# M55M1 register map
File version: 1.0
Registers are 32-bit, read-write, reset 0x0 unless marked. A register's access mark holds for its fields unless they carry their own. Offsets are from the block's base; [hi:lo] are bit positions.

## LPSPI_NS — LPSPI Register Map
Base 0x50444000
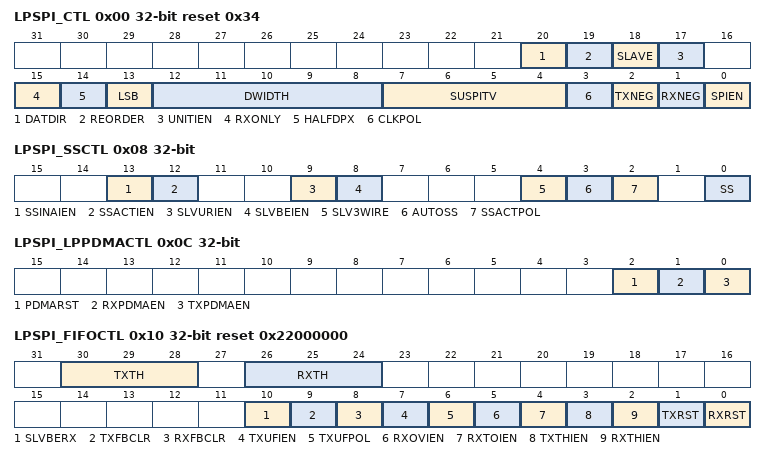
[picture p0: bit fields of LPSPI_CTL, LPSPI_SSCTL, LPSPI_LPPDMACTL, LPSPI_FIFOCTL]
0x00 LPSPI_CTL reset 0x34 — LPSPI Control Register
  [20] DATDIR — Data Port Direction Control. This bit is used to select the data input/output direction in half-duplex transfer and Dual transfer
    0=LPSPI data is input direction; 1=LPSPI data is output direction
  [19] REORDER — Byte Reorder Function Enable Bit. Note: Byte Reorder function is only available if DWIDTH is defined as 16, 24, and 32 bits.
    0=Byte Reorder function Disabled; 1=Byte Reorder function Enabled. A byte suspend interval will be inserted among each byte. The period of the byte suspend interval depends on the setting of SUSPITV
  [18] SLAVE — Slave Mode Control
    0=Master mode; 1=Slave mode
  [17] UNITIEN — Unit Transfer Interrupt Enable Bit
    0=LPSPI unit transfer interrupt Disabled; 1=LPSPI unit transfer interrupt Enabled
  [15] RXONLY — Receive-only Mode Enable Bit. This bit field is only available in Master mode. In receive-only mode, LPSPI Master will generate LPSPI bus clock continuously for receiving data bit from LPSPI slave device and assert the BUSY status. Note: This bit is for Master Mode only.
    0=Receive-only mode Disabled; 1=Receive-only mode Enabled
  [14] HALFDPX — LPSPI Half-duplex Transfer Enable Bit. This bit is used to select full-duplex or half-duplex for LPSPI transfer. The bit field DATDIR (LPSPI_CTL[20]) can be used to set the data direction in half-duplex transfer.
    0=LPSPI operates in full-duplex transfer; 1=LPSPI operates in half-duplex transfer
  [13] LSB — Send LSB First
    0=The MSB, which bit of transmit/receive register depends on the setting of DWIDTH, is transmitted/received first; 1=The LSB, bit 0 of the LPSPI TX register, is sent first to the LPSPI data output pin, and the first bit received from the LPSPI data input pin will be put in the LSB position of the RX register (bit 0 of LPSPI_RX)
  [12:8] DWIDTH — Data Width. This field specifies how many bits can be transmitted/received in one transaction. The minimum bit length is 4 bits and can up to 32 bits. Note: This bit field will decide the depth of TX/RX FIFO configuration in LPSPI mode. Therefore, changing this bit field will clear TX/RX FIFO by hardware automatically.
  [7:4] SUSPITV — Suspend Interval. The four bits provide configurable suspend interval between two successive transmit/receive transaction in a transfer. The definition of the suspend interval is the interval between the last clock edge of the preceding transaction word and the first clock edge of the following transaction word. The default value is 0x3. The period of the suspend interval is obtained according to the following equation. (SUSPITV[3:0] + 0.5) * period of LPSPI_CLK clock cycle. Example: Note: These bits are for Master Mode only.
  [3] CLKPOL — Clock Polarity
    0=LPSPI bus clock is idle low; 1=LPSPI bus clock is idle high
  [2] TXNEG — Transmit on Negative Edge
    0=Transmitted data output signal is changed on the rising edge of LPSPI bus clock; 1=Transmitted data output signal is changed on the falling edge of LPSPI bus clock
  [1] RXNEG — Receive on Negative Edge
    0=Received data input signal is latched on the rising edge of LPSPI bus clock; 1=Received data input signal is latched on the falling edge of LPSPI bus clock
  [0] SPIEN — LPSPI Transfer Control Enable Bit. In Master mode, the transfer will start when there is data in the FIFO buffer after this bit is set to 1. In Slave mode, this device is ready to receive data when this bit is set to 1. Note: Before changing the configurations of LPSPI_CTL, LPSPI_CLKDIV, LPSPI_SSCTL and LPSPI_FIFOCTL registers, user shall clear the SPIEN (LPSPI_CTL[0]) and confirm the SPIENSTS (LPSPI_STATUS[15]) is 0.
    0=Transfer control Disabled; 1=Transfer control Enabled
0x04 LPSPI_CLKDIV — LPSPI Clock Divider Register
  [8:0] DIVIDER — Clock Divider. The value in this field is the frequency divider for generating the peripheral clock, fspi_eclk, and the LPSPI bus clock of LPSPI Master. The frequency is obtained according to the following equation. where is the peripheral clock source, which is defined in the clock control register, CLK_CLKSEL2 or CLK_CLKSEL3. Note 1: The time interval must be larger than or equal to 8 peripheral clock cycles between releasing LPSPI IP software reset and setting this clock divider register.
0x08 LPSPI_SSCTL — LPSPI Slave Select Control Register
  [13] SSINAIEN — Slave Select Inactive Interrupt Enable Bit
    0=Slave select inactive interrupt Disabled; 1=Slave select inactive interrupt Enabled
  [12] SSACTIEN — Slave Select Active Interrupt Enable Bit
    0=Slave select active interrupt Disabled; 1=Slave select active interrupt Enabled
  [9] SLVURIEN — Slave Mode TX Under Run Interrupt Enable Bit
    0=Slave mode TX under run interrupt Disabled; 1=Slave mode TX under run interrupt Enabled
  [8] SLVBEIEN — Slave Mode Bit Count Error Interrupt Enable Bit
    0=Slave mode bit count error interrupt Disabled; 1=Slave mode bit count error interrupt Enabled
  [4] SLV3WIRE — Slave 3-wire Mode Enable Bit. In Slave 3-wire mode, the LPSPI controller can work with 3-wire interface including LPSPI_CLK, LPSPI_MISO and LPSPI_MOSI pins. Note: This bit is for Slave Mode only.
    0=4-wire bi-direction interface; 1=3-wire bi-direction interface
  [3] AUTOSS — Automatic Slave Selection Function Enable Bit. Note: This bit is for Master Mode only.
    0=Automatic slave selection function Disabled. Slave selection signal will be asserted/de-asserted according to SS (LPSPI_SSCTL[0]); 1=Automatic slave selection function Enabled
  [2] SSACTPOL — Slave Selection Active Polarity. This bit defines the active polarity of slave selection signal (LPSPI_SS).
    0=The slave selection signal LPSPI_SS is active low; 1=The slave selection signal LPSPI_SS is active high
  [0] SS — Slave Selection Control. If AUTOSS bit is cleared to 0, Note: This bit is for Master Mode only.
    0=set the LPSPI_SS line to inactive state. Keep the LPSPI_SS line at inactive state; 1=set the LPSPI_SS line to active state. LPSPI_SS line will be automatically driven to active state for the duration of data transfer, and will be driven to inactive state for the rest of the time. The active state of LPSPI_SS is specified in SSACTPOL (LPSPI_SSCTL[2])
0x0C LPSPI_LPPDMACTL — LPSPI LPPDMA Control Register
  [2] PDMARST — PDMA Reset
    0=No effect; 1=Reset the LPPDMA control logic of the LPSPI controller. This bit will be automatically cleared to 0
  [1] RXPDMAEN — Receive LPPDMA Enable Bit
    0=Receive LPPDMA function Disabled; 1=Receive LPPDMA function Enabled
  [0] TXPDMAEN — Transmit LPPDMA Enable Bit. Note 1: In LPSPI Master mode with full duplex transfer, if both TX and RX LPPDMA functions are enabled, RX LPPDMA function cannot be enabled prior to TX LPPDMA function. User can enable TX LPPDMA function firstly or enable both functions simultaneously. Note 2: In LPSPI Master mode with full duplex transfer, if both TX and RX LPPDMA functions are enabled, TX LPPDMA function cannot be disabled prior to RX LPPDMA function. User can disable RX LPPDMA function firstly or disable both functions simultaneously.
    0=Transmit LPPDMA function Disabled; 1=Transmit LPPDMA function Enabled
0x10 LPSPI_FIFOCTL reset 0x22000000 — LPSPI FIFO Control Register
  [30:28] TXTH — Transmit FIFO Threshold. If the valid data count of the transmit FIFO buffer is less than or equal to the TXTH setting, the TXTHIF bit will be set to 1, else the TXTHIF bit will be cleared to 0. The MSB of this bit field is only meaningful while LPSPI mode 4~16 bits of data length.
  [26:24] RXTH — Receive FIFO Threshold. If the valid data count of the receive FIFO buffer is larger than the RXTH setting, the RXTHIF bit will be set to 1, else the RXTHIF bit will be cleared to 0. The MSB of this bit field is only meaningful while LPSPI mode 4~16 bits of data length.
  [10] SLVBERX — RX FIFO Write Data Enable Bit When Slave Mode Bit Count Error. Note: This bit is for Slave Mode only.
    0=Uncompleted RX data will be dropped from RX FIFO when bit count error event happened in LPSPI Slave mode; 1=Uncompleted RX data will be written into RX FIFO when bit count error event happened in LPSPI Slave mode. User can read SLVBENUM (LPSPI_STATUS2[29:24]) to know that the effective bit number of uncompleted RX data when LPSPI slave bit count error happened
  [9] TXFBCLR — Transmit FIFO Buffer Clear. Note: The TX shift register will not be cleared.
    0=No effect; 1=Clear transmit FIFO pointer. The TXFULL bit will be cleared to 0 and the TXEMPTY bit will be set to 1. This bit will be cleared to 0 by hardware about 1 system clock after it is set to 1
  [8] RXFBCLR — Receive FIFO Buffer Clear. Note: The RX shift register will not be cleared.
    0=No effect; 1=Clear receive FIFO pointer. The RXFULL bit will be cleared to 0 and the RXEMPTY bit will be set to 1. This bit will be cleared to 0 by hardware about 1 system clock after it is set to 1
  [7] TXUFIEN — TX Underflow Interrupt Enable Bit. When TX underflow event occurs in Slave mode, TXUFIF (LPSPI_STATUS[19]) will be set to 1. This bit is used to enable the TX underflow interrupt.
    0=Slave TX underflow interrupt Disabled; 1=Slave TX underflow interrupt Enabled
  [6] TXUFPOL — TX Underflow Data Polarity. Note 1: The TX underflow event occurs if there is no any data in TX FIFO when the slave selection signal is active. Note 2: When TX underflow event occurs, LPSPI_MISO pin state will be determined by this setting even though TX FIFO is not empty afterward. Data stored in TX FIFO will be sent through LPSPI_MISO pin in the next transfer frame.
    0=The LPSPI data out keeps 0 if there is TX underflow event in Slave mode; 1=The LPSPI data out keeps 1 if there is TX underflow event in Slave mode
  [5] RXOVIEN — Receive FIFO Overrun Interrupt Enable Bit
    0=Receive FIFO overrun interrupt Disabled; 1=Receive FIFO overrun interrupt Enabled
  [4] RXTOIEN — Receive Time-out Interrupt Enable Bit
    0=Receive time-out interrupt Disabled; 1=Receive time-out interrupt Enabled
  [3] TXTHIEN — Transmit FIFO Threshold Interrupt Enable Bit
    0=TX FIFO threshold interrupt Disabled; 1=TX FIFO threshold interrupt Enabled
  [2] RXTHIEN — Receive FIFO Threshold Interrupt Enable Bit
    0=RX FIFO threshold interrupt Disabled; 1=RX FIFO threshold interrupt Enabled
  [1] TXRST — Transmit Reset. Note: If TX underflow event occurs in LPSPI Slave mode, this bit can be used to make LPSPI return to idle state.
    0=No effect; 1=Reset transmit FIFO pointer and transmit circuit. The TXFULL bit will be cleared to 0 and the TXEMPTY bit will be set to 1. This bit will be cleared to 0 by hardware about 3 system clock cycles + 2 peripheral clock cycles after it is set to 1. User can read TXRXRST (LPSPI_STATUS[23]) to check if reset is accomplished or not
  [0] RXRST — Receive Reset
    0=No effect; 1=Reset receive FIFO pointer and receive circuit. The RXFULL bit will be cleared to 0 and the RXEMPTY bit will be set to 1. This bit will be cleared to 0 by hardware about 3 system clock cycles + 2 peripheral clock cycles after it is set to 1. User can read TXRXRST (LPSPI_STATUS[23]) to check if reset is accomplished or not
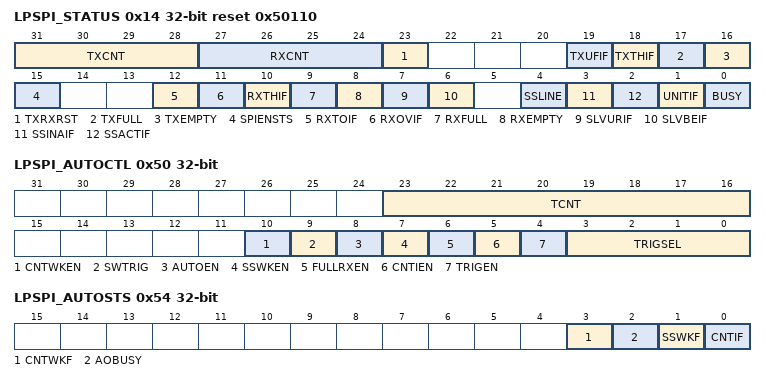
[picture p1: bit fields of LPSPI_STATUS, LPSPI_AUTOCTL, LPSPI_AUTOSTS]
0x14 LPSPI_STATUS reset 0x50110
  [31:28] TXCNT ro — Transmit FIFO Data Count (Read Only). This bit field indicates the valid data count of transmit FIFO buffer.
  [27:24] RXCNT ro — Receive FIFO Data Count (Read Only). This bit field indicates the valid data count of receive FIFO buffer.
  [23] TXRXRST ro — TX or RX Reset Status (Read Only). Note: Both the reset operations of TXRST and RXRST need 3 system clock cycles + 2 peripheral clock cycles. User can check the status of this bit to monitor the reset function is doing or done.
    0=The reset function of TXRST or RXRST is done; 1=Doing the reset function of TXRST or RXRST
  [19] TXUFIF — TX Underflow Interrupt Flag. When the TX underflow event occurs, this bit will be set to 1, the state of data output pin depends on the setting of TXUFPOL. Note 1: This bit will be cleared by writing 1 to it. Note 2: If reset slave's transmission circuit when slave selection signal is active, this flag will be set to 1 after 2 peripheral clock cycles + 3 system clock cycles since the reset operation is done.
    0=No effect; 1=No data in Transmit FIFO and TX shift register when the slave selection signal is active
  [18] TXTHIF ro — Transmit FIFO Threshold Interrupt Flag (Read Only)
    0=The valid data count within the transmit FIFO buffer is larger than the setting value of TXTH; 1=The valid data count within the transmit FIFO buffer is less than or equal to the setting value of TXTH
  [17] TXFULL ro — Transmit FIFO Buffer Full Indicator (Read Only)
    0=Transmit FIFO buffer is not full; 1=Transmit FIFO buffer is full
  [16] TXEMPTY ro — Transmit FIFO Buffer Empty Indicator (Read Only)
    0=Transmit FIFO buffer is not empty; 1=Transmit FIFO buffer is empty
  [15] SPIENSTS ro — LPSPI Enable Status (Read Only). Note: The LPSPI peripheral clock is asynchronous with the system clock. In order to make sure the LPSPI control logic is disabled, this bit indicates the real status of LPSPI controller.
    0=LPSPI controller Disabled; 1=LPSPI controller Enabled
  [12] RXTOIF — Receive Time-out Interrupt Flag. Note: This bit will be cleared by writing 1 to it.
    0=No receive FIFO time-out event; 1=Receive FIFO buffer is not empty and no read operation on receive FIFO buffer over 64 LPSPI peripheral clock periods in Master mode or over 576 LPSPI peripheral clock periods in Slave mode. When the received FIFO buffer is read by software, the time-out status will be cleared automatically
  [11] RXOVIF — Receive FIFO Overrun Interrupt Flag. When the receive FIFO buffer is full, the follow-up data will be dropped and this bit will be set to 1. Note: This bit will be cleared by writing 1 to it.
    0=No FIFO is overrun; 1=Receive FIFO is overrun
  [10] RXTHIF ro — Receive FIFO Threshold Interrupt Flag (Read Only)
    0=The valid data count within the receive FIFO buffer is smaller than or equal to the setting value of RXTH; 1=The valid data count within the receive FIFO buffer is larger than the setting value of RXTH
  [9] RXFULL ro — Receive FIFO Buffer Full Indicator (Read Only)
    0=Receive FIFO buffer is not full; 1=Receive FIFO buffer is full
  [8] RXEMPTY ro — Receive FIFO Buffer Empty Indicator (Read Only)
    0=Receive FIFO buffer is not empty; 1=Receive FIFO buffer is empty
  [7] SLVURIF — Slave Mode TX Under Run Interrupt Flag. In Slave mode, if TX underflow event occurs and the slave select line goes to inactive state, this interrupt flag will be set to 1. Note: This bit will be cleared by writing 1 to it.
    0=No Slave TX under run event; 1=Slave TX under run event occurred
  [6] SLVBEIF — Slave Mode Bit Count Error Interrupt Flag. In Slave mode, when the slave select line goes to inactive state, if bit counter is mismatch with DWIDTH, this interrupt flag will be set to 1. Note: If the slave select active but there is no any bus clock input, the SLVBEIF also active when the slave select goes to inactive state. This bit will be cleared by writing 1 to it.
    0=No Slave mode bit count error event; 1=Slave mode bit count error event occurred
  [4] SSLINE ro — Slave Select Line Bus Status (Read Only). Note: This bit is only available in Slave mode. If SSACTPOL (LPSPI_SSCTL[2]) is set 0, and the SSLINE is 1, the LPSPI slave select is in inactive status.
    0=The slave select line status is 0; 1=The slave select line status is 1
  [3] SSINAIF — Slave Select Inactive Interrupt Flag. Note: Only available in Slave mode. This bit will be cleared by writing 1 to it.
    0=Slave select inactive interrupt was cleared or not occurred; 1=Slave select inactive interrupt event occurred
  [2] SSACTIF — Slave Select Active Interrupt Flag. Note: Only available in Slave mode. This bit will be cleared by writing 1 to it.
    0=Slave select active interrupt was cleared or not occurred; 1=Slave select active interrupt event occurred
  [1] UNITIF — Unit Transfer Interrupt Flag. Note: This bit will be cleared by writing 1 to it.
    0=No transaction has been finished since this bit was cleared to 0; 1=LPSPI controller has finished one unit transfer
  [0] BUSY ro — Busy Status (Read Only). Note: By applications, this LPSPI busy flag should be used with other status registers in LPSPI_STATUS such as TXCNT, RXCNT, TXTHIF, TXFULL, TXEMPTY, RXTHIF, RXFULL, RXEMPTY, and UNITIF. Therefore the LPSPI transfer done events of TX/RX operations can be obtained at correct timing point.
    0=LPSPI controller is in idle state; 1=LPSPI controller is in busy state
0x18 LPSPI_STATUS2 ro
  [29:24] SLVBENUM — Effective Bit Number of Uncompleted RX Data. This status register indicates that effective bit number of uncompleted RX data when SLVBERX (LPSPI_FIFOCTL[10]) is enabled and RX bit count error event happen in LPSPI Slave mode. This status register will be fixed to 0x0 when SLVBERX (LPSPI_FIFOCTL[10]) is disabled. Note 1: This register will be cleared to 0x0 when user writes 0x1 to SLVBEIF (LPSPI_STATUS[6]). Note 2: This bit is for Slave Mode only.
0x20 LPSPI_TX wo — LPSPI Data Transmit Register
  [31:0] TX — Data Transmit Register. The data transmit registers pass through the transmitted data into the 4-level transmit FIFO buffers. The number of valid bits depends on the setting of DWIDTH (LPSPI_CTL[12:8]) in LPSPI mode. In LPSPI mode, if DWIDTH is set to 0x08, the bits TX[7:0] will be transmitted. If DWIDTH is set to 0x00, the LPSPI controller will perform a 32-bit transfer. Note: In Master mode, LPSPI controller will start to transfer the LPSPI bus clock after 1 APB clock and 6 peripheral clock cycles after user writes to this register.
0x30 LPSPI_RX ro — LPSPI Data Receive Register
  [31:0] RX — Data Receive Register (Read Only). There are 4-level FIFO buffers in this controller. The data receive register holds the data received from LPSPI data input pin. If the RXEMPTY (LPSPI_STATUS[8]) is not set to 1, the receive FIFO buffers can be accessed through software by reading this register.
0x50 LPSPI_AUTOCTL — LPSPI Automatic Operation Control Register
  [23:16] TCNT — Auomatic Operation RX Transfer Count. In Auomatic Operation Master mode, TCNT represents the required number of RX data received from external LPSPI slave device while in RX Phase. The maximum transfer count is 255.
  [10] CNTWKEN — TCNT Count Match Wake Up Enable Bit. Note: If TCNT is set to 0, TCNT count match wake-up function will remain disabled even if CNTWKEN is set to 1.
    0=TCNT count match wake-up function Disabled; 1=TCNT count match wake-up function Enabled
  [9] SWTRIG wo — Software Trigger (Write Only). After AUTOEN set to 1, software can manually trigger the Automatic Operation Master mode by writing 1 to this bit.
  [8] AUTOEN — Automatic Operation Mode Enable Bit
    0=Automatic operation master mode Disabled; 1=Automatic operation master mode Enabled
  [7] SSWKEN — Slave Select Wake Up Enable Bit. In Slave mode, the CPU will be woken up by SS falling or rising edge in NPDx mode after this bit is set to 1.
    0=LPSPI SS wake-up function Disabled; 1=LPSPI SS wake-up function Enabled
  [6] FULLRXEN — Full RX Data Acception Enable Bit. In Auomatic Operation Master mode and LPSPI operates in full-duplex mode, the RX data will be saved from RX buffer by LPPDMA while in TX Phase after this bit is set to 1.
  [5] CNTIEN — TCNT Count Match Interrupt Enable
    0=TCNT count match interrupt Disabled; 1=TCNT count match interrupt Enabled
  [4] TRIGEN — Automatic Operation Trigger Enable Bit. In Auomatic Operation Master mode, the automatic operation of LPSPI will be triggered by a event sent from the trigger source selected by TRIGSEL[3:0] after this bit is set to 1.
    0=LPSPI Automatic Operation Trigger Disabled; 1=LPSPI Automatic Operation Trigger Enabled
  [3:0] TRIGSEL — Automatic Operation Trigger Source Select
    0=Low Power Auto-operation Trigger Source from LPTMR0; 1=Low Power Auto-operation Trigger Source from LPTMR1; 2=Low Power Auto-operation Trigger Source from TTMR0; 3=Low Power Auto-operation Trigger Source from TTMR1; 4=Low Power Auto-operation Trigger Source from LPGPIO0 (PA.0); 5=Low Power Auto-operation Trigger Source from LPGPIO1 (PB.0); 6=Low Power Auto-operation Trigger Source from LPGPIO2 (PC.0); 7=Low Power Auto-operation Trigger Source from LPGPIO3 (PD.0)
0x54 LPSPI_AUTOSTS — LPSPI Automatic Operation Status Register
  [3] CNTWKF — TCNT Count Match Wake Up Flag. When chip is woken up due to the received data count matching the setting value of TCNT, this bit will be set to 1. Software can write 1 to clear this bit.
  [2] AOBUSY — Automatic Operation Busy Flag. When there were one or more requests from trigger sources during auto operation, this bit will be set to 1. Software can write 1 to clear this bit.
  [1] SSWKF — Slave Select Wake Up Flag. In Slave mode, when chip is woken up from NPDx mode by LPSPI, this bit is set to 1. Software can write 1 to clear this bit.
  [0] CNTIF — TCNT Count Match Interrupt Flag. When the received data count matchs the setting value of TCNT, this bit will be set to 1. Software can write 1 to clear this bit.
    0=The received data count is less than the setting value of TCNT; 1=The received data count is equal than the setting value of TCNT
